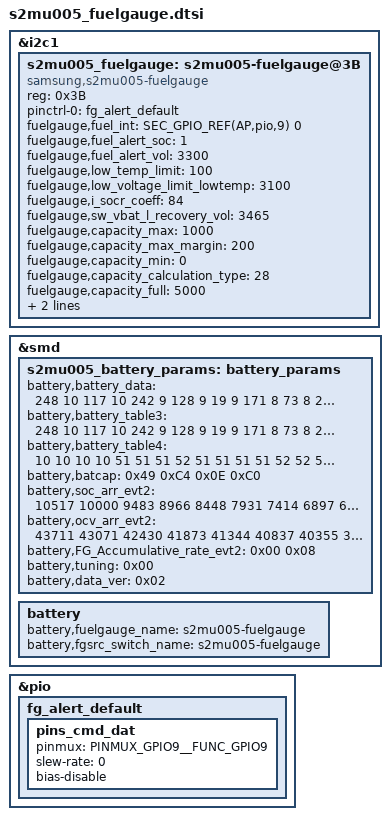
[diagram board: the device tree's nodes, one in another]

&i2c1 {
	status = "okay";

	s2mu005_fuelgauge: s2mu005-fuelgauge@3B {
		compatible = "samsung,s2mu005-fuelgauge";
		reg = <0x3B>;
		pinctrl-names = "default";
		pinctrl-0 = <&fg_alert_default>;
		fuelgauge,fuel_int = <SEC_GPIO_REF(AP,pio,9) 0>;
		fuelgauge,fuel_alert_soc = <1>;
		fuelgauge,fuel_alert_vol = <3300>;
		fuelgauge,low_temp_limit = <100>;
		fuelgauge,low_voltage_limit_lowtemp = <3100>;
		fuelgauge,i_socr_coeff = <84>;
		fuelgauge,sw_vbat_l_recovery_vol = <3465>;
		fuelgauge,capacity_max = <1000>;
		fuelgauge,capacity_max_margin = <200>;
		fuelgauge,capacity_min = <0>;
		fuelgauge,capacity_calculation_type = <28>;
		fuelgauge,capacity_full = <3000>;
		fuelgauge,type_str = "SDI";
		fuelgauge,fg_log_enable = <1>;
	};
};

&smd {
	s2mu005_battery_params: battery_params {
		battery,battery_data =
		<
			/***** battery data for 4.35 *****/
			/* battery,battery_table3 */
			6 11 132 10 1 10 138 9 23 9
			171 8 70 8 233 7 155 7 61 7
			223 6 169 6 128 6 96 6 70 6
			42 6 1 6 211 5 146 5 123 5
			223 3 7 2 107 8 0 8 149 7
			43 7 192 6 85 6 235 5 128 5
			21 5 171 4 64 4 213 3 107 3
			0 3 149 2 43 2 192 1 85 1
			235 0 128 0 21 0 241 15

			/* battery,battery_table4 */
			10 10 10 10 48 47 48 47 47 47
			47 48 49 50 51 54 57 64 77 106
			158 221

			/* battery,batcap */
			0x2B 0x14 0x8 0x13 /* [0x0F] [0x0E] [0x11] [0x10] */

			/* battery,accum */
			0x00 0x08 /* [0x44] [0x45] */

			/* battery,soc_arr_val */
			10521 10000 9479 8958 8438 7917 7396 6875 6354 5833
			5312 4791 4271 3750 3229 2708 2187 1667 1146 625
			104 (-75)

			/* battery,ocv_arr_val */
			43778 43142 42507 41922 41362 40834 40339 39890 39508 39047
			38588 38327 38126 37968 37843 37707 37507 37281 36962 36850
			34840 32536

			/* battery,tuning */
			0x00 /* [0x13] */

			/***** battery data for 4.33 *****/
			/* battery,battery_table3 */
			6 11 132 10 1 10 138 9 23 9
			171 8 70 8 233 7 155 7 61 7
			223 6 169 6 128 6 96 6 70 6
			42 6 1 6 211 5 146 5 123 5
			223 3 7 2 132 8 24 8 172 7
			65 7 213 6 105 6 253 5 145 5
			37 5 185 4 77 4 225 3 117 3
			9 3 157 2 49 2 197 1 89 1
			237 0 130 0 22 0 240 15

			/* battery,battery_table4 */
			10 10 10 10 48 47 48 47 47 47
			47 48 49 50 51 54 57 64 77 106
			158 221

			/* battery,batcap */
			0x2B 0x48 0x8 0x1D /* [0x0F] [0x0E] [0x11] [0x10] */

			/* battery,accum */
			0x00 0x8 /* [0x44] [0x45] */

			/* battery,soc_arr_val */
			10646 10119 9592 9065 8538 8011 7484 6957 6430 5903
			5376 4849 4321 3794 3267 2740 2213 1686 1159 632
			105 (-76)

			/* battery,ocv_arr_val */
			43778 43142 42507 41922 41362 40834 40339 39890 39508 39047
			38588 38327 38126 37968 37843 37707 37507 37281 36962 36850
			34840 32536

			/* battery,tuning */
			0x00 /* [0x13] */

			/***** battery data for 4.31 *****/
			/* battery,battery_table3 */
			6 11 132 10 1 10 138 9 23 9
			171 8 70 8 233 7 155 7 61 7
			223 6 169 6 128 6 96 6 70 6
			42 6 1 6 211 5 146 5 123 5
			223 3 7 2 203 8 92 8 236 7
			125 7 13 7 158 6 46 6 191 5
			79 5 224 4 113 4 1 4 146 3
			34 3 179 2 67 2 212 1 101 1
			245 0 134 0 22 0 240 15

			/* battery,battery_table4 */
			10 10 10 10 48 47 48 47 47 47
			47 48 49 50 51 54 57 64 77 106
			158 221

			/* battery,batcap */
			0x29 0xEC 0x7 0xDC /* [0x0F] [0x0E] [0x11] [0x10] */

			/* battery,accum */
			0x00 0x8 /* [0x44] [0x45] */

			/* battery,soc_arr_val */
			10992 10448 9903 9359 8815 8271 7727 7182 6638 6094
			5550 5006 4462 3918 3373 2829 2285 1741 1197 653
			109 (-79)

			/* battery,ocv_arr_val */
			43778 43142 42507 41922 41362 40834 40339 39890 39508 39047
			38588 38327 38126 37968 37843 37707 37507 37281 36962 36850
			34840 32536

			/* battery,tuning */
			0x00 /* [0x13] */

			/***** battery data for 4.29 *****/
			/* battery,battery_table3 */
			6 11 132 10 1 10 138 9 23 9
			171 8 70 8 233 7 155 7 61 7
			223 6 169 6 128 6 96 6 70 6
			42 6 1 6 211 5 146 5 123 5
			223 3 7 2 166 8 56 8 203 7
			93 7 240 6 130 6 20 6 167 5
			57 5 203 4 94 4 240 3 131 3
			21 3 167 2 58 2 204 1 95 1
			241 0 132 0 22 0 240 15

			/* battery,battery_table4 */
			10 10 10 10 48 47 48 47 47 47
			47 48 49 50 51 54 57 64 77 106
			158 221

			/* battery,batcap */
			0x2A 0xA0 0x7 0xFE /* [0x0F] [0x0E] [0x11] [0x10] */

			/* battery,accum */
			0x00 0x8 /* [0x44] [0x45] */

			/* battery,soc_arr_val */
			10810 10275 9740 9205 8670 8135 7599 7064 6529 5993
			5458 4923 4388 3853 3318 2783 2248 1712 1177 642
			107 (-77)

			/* battery,ocv_arr_val */
			43778 43142 42507 41922 41362 40834 40339 39890 39508 39047
			38588 38327 38126 37968 37843 37707 37507 37281 36962 36850
			34840 32536

			/* battery,tuning */
			0x00 /* [0x13] */

			/***** battery data for 4.24 *****/
			/* battery,battery_table3 */
			6 11 132 10 1 10 138 9 23 9
			171 8 70 8 233 7 155 7 61 7
			223 6 169 6 128 6 96 6 70 6
			42 6 1 6 211 5 146 5 123 5
			223 3 7 2 53 9 192 8 75 8
			215 7 98 7 237 6 121 6 4 6
			143 5 27 5 166 4 49 4 189 3
			72 3 211 2 95 2 234 1 117 1
			1 1 140 0 23 0 239 15

			/* battery,battery_table4 */
			10 10 10 10 48 47 48 47 47 47
			47 48 49 50 51 54 57 64 77 106
			158 221

			/* battery,batcap */
			0x28 0xC 0x7 0x82 /* [0x0F] [0x0E] [0x11] [0x10] */

			/* battery,accum */
			0x00 0x8 /* [0x44] [0x45] */

			/* battery,soc_arr_val */
			11507 10937 10367 9798 9228 8659 8089 7519 6949 6380
			5810 5240 4671 4101 3532 2962 2392 1823 1253 684
			114 (-82)

			/* battery,ocv_arr_val */
			43778 43142 42507 41922 41362 40834 40339 39890 39508 39047
			38588 38327 38126 37968 37843 37707 37507 37281 36962 36850
			34840 32536

			/* battery,tuning */
			0x00 /* [0x13] */
			>;

		battery,battery_table3 = <
			6 11 132 10 1 10 138 9 23 9
			171 8 70 8 233 7 155 7 61 7
			223 6 169 6 128 6 96 6 70 6
			42 6 1 6 211 5 146 5 123 5
			223 3 7 2 107 8 0 8 149 7
			43 7 192 6 85 6 235 5 128 5
			21 5 171 4 64 4 213 3 107 3
			0 3 149 2 43 2 192 1 85 1
			235 0 128 0 21 0 241 15
			>;

		battery,battery_table4 = <
			10 10 10 10 48 47 48 47 47 47
			47 48 49 50 51 54 57 64 77 106
			158 221
			>;

		battery,batcap = <0x2B 0x14 0x8 0x13>; /* [0x0F] [0x0E] [0x11] [0x10] */

		battery,soc_arr_evt2 = <
			10521 10000 9479 8958 8438 7917 7396 6875 6354 5833
			5312 4791 4271 3750 3229 2708 2187 1667 1146 625
			104 (-75)
			>;
		battery,ocv_arr_evt2 = <
			43778 43142 42507 41922 41362 40834 40339 39890 39508 39047
			38588 38327 38126 37968 37843 37707 37507 37281 36962 36850
			34840 32536
			>;
		battery,FG_Accumulative_rate_evt2 = <0x00 0x08>; /* 0x44 0x45 */
		battery,tuning = <0x00>; /* [0x13] */
		battery,data_ver = <0x04>;
	};
};

&smd {
	battery {
		battery,fuelgauge_name = "s2mu005-fuelgauge";
		battery,fgsrc_switch_name = "s2mu005-fuelgauge"; /* Fuelgauge voltage source */
	};
};

/* /home/dpi/qb5_8814/workspace/P4_1716/android/kernel/kmodule/battery/fuelgauge/s2mu005_fuelgauge/s2mu005_fuelgauge.a02.dtsi */

&pio {
	fg_alert_default: fg_alert_default {
		pins_cmd_dat {
			pinmux = <PINMUX_GPIO9__FUNC_GPIO9>;
			slew-rate = <0>;
			bias-disable;
		};
	};
};

&s2mu005_fuelgauge {
	fuelgauge,capacity_full = <5000>;
};

&s2mu005_battery_params {
	battery,battery_data =
	<
		/***** battery data for 4.35 *****/
		/* battery,battery_table3 */
		248 10 117 10 242 9 128 9 19 9
		171 8 73 8 208 7 156 7 70 7
		230 6 172 6 130 6 97 6 71 6
		45 6 7 6 223 5 155 5 130 5
		152 4 156 1 106 8 0 8 150 7
		44 7 194 6 88 6 238 5 132 5
		26 5 177 4 71 4 221 3 115 3
		9 3 159 2 53 2 203 1 97 1
		247 0 141 0 35 0 227 15

		/* battery,battery_table4 */
		10 10 10 10 51 51 51 52 51 51
		51 51 52 52 52 53 54 55 57 60
		65 154

		/* battery,batcap */
		0x49 0xC4 0x0E 0xC0 /* [0x0F] [0x0E] [0x11] [0x10] */

		/* battery,accum */
		0x00 0x08 /* [0x44] [0x45] */

		/* battery,soc_arr_val */
		10517 10000 9483 8966 8448 7931 7414 6897 6379 5862
		5345 4828 4310 3793 3276 2759 2241 1724 1207 690
		172 (-141)

		/* battery,ocv_arr_val */
		43711 43071 42430 41873 41344 40837 40355 39768 39513 39091
		38625 38338 38133 37972 37846 37721 37533 37336 37007 36884
		35744 32014

		/* battery,tuning */
		0x00 /* [0x13] */

		/***** battery data for 4.33 *****/
		/* battery,battery_table3 */
		233 10 108 10 239 9 123 9 11 9
		162 8 62 8 229 7 150 7 35 7
		216 6 166 6 126 6 94 6 68 6
		36 6 250 5 201 5 139 5 120 5
		98 3 90 1 118 8 11 8 159 7
		51 7 199 6 92 6 240 5 132 5
		24 5 173 4 65 4 213 3 105 3
		254 2 146 2 38 2 186 1 79 1
		227 0 119 0 11 0 136 15

		/* battery,battery_table4 */
		10 10 10 10 54 54 54 54 54 54
		54 54 55 55 56 56 56 57 59 63
		76 101

		/* battery,batcap */
		0x4B 0x5C 0x0F 0x12 /* [0x0F] [0x0E] [0x11] [0x10] */

		/* battery,accum */
		0x00 0x8 /* [0x44] [0x45] */

		/* battery,soc_arr_val */
		10578 10052 9525 8999 8473 7947 7421 6895 6369 5842
		5316 4790 4264 3738 3212 2686 2160 1633 1107 581
		55 (-584)

		/* battery,ocv_arr_val */
		43638 43028 42419 41849 41305 40789 40302 39869 39480 38923
		38557 38311 38115 37959 37830 37674 37472 37233 36929 36837
		34229 31691

		/* battery,tuning */
		0x00 /* [0x13] */

		/***** battery data for 4.31 *****/
		/* battery,battery_table3 */
		233 10 108 10 239 9 123 9 11 9
		162 8 62 8 229 7 150 7 35 7
		216 6 166 6 126 6 94 6 68 6
		36 6 250 5 201 5 139 5 120 5
		98 3 90 1 159 8 49 8 195 7
		85 7 232 6 122 6 12 6 158 5
		49 5 195 4 85 4 231 3 122 3
		12 3 158 2 48 2 195 1 85 1
		231 0 121 0 12 0 136 15

		/* battery,battery_table4 */
		10 10 10 10 54 54 54 54 54 54
		54 54 55 55 56 56 56 57 59 63
		76 101

		/* battery,batcap */
		0x49 0xF8 0x0E 0xCB /* [0x0F] [0x0E] [0x11] [0x10] */

		/* battery,accum */
		0x00 0x8 /* [0x44] [0x45] */

		/* battery,soc_arr_val */
		10774 10238 9702 9166 8630 8094 7559 7023 6487 5951
		5415 4879 4343 3807 3271 2736 2200 1664 1128 592
		56 (-586)

		/* battery,ocv_arr_val */
		43638 43028 42419 41849 41305 40789 40302 39869 39480 38923
		38557 38311 38115 37959 37830 37674 37472 37233 36929 36837
		34229 31691

		/* battery,tuning */
		0x00 /* [0x13] */

		/***** battery data for 4.29 *****/
		/* battery,battery_table3 */
		233 10 108 10 239 9 123 9 11 9
		162 8 62 8 229 7 150 7 35 7
		216 6 166 6 126 6 94 6 68 6
		36 6 250 5 201 5 139 5 120 5
		98 3 90 1 203 8 91 8 235 7
		123 7 11 7 155 6 43 6 187 5
		75 5 219 4 107 4 251 3 139 3
		27 3 171 2 60 2 204 1 92 1
		236 0 124 0 12 0 136 15

		/* battery,battery_table4 */
		10 10 10 10 54 54 54 54 54 54
		54 54 55 55 56 56 56 57 59 63
		76 101

		/* battery,batcap */
		0x48 0x84 0x0E 0x80 /* [0x0F] [0x0E] [0x11] [0x10] */

		/* battery,accum */
		0x00 0x8 /* [0x44] [0x45] */

		/* battery,soc_arr_val */
		10990 10443 9897 9350 8803 8257 7710 7163 6617 6070
		5524 4977 4430 3884 3337 2790 2244 1697 1150 604
		57 (-588)

		/* battery,ocv_arr_val */
		43638 43028 42419 41849 41305 40789 40302 39869 39480 38923
		38557 38311 38115 37959 37830 37674 37472 37233 36929 36837
		34229 31691

		/* battery,tuning */
		0x00 /* [0x13] */

		/***** battery data for 4.24 *****/
		/* battery,battery_table3 */
		233 10 108 10 239 9 123 9 11 9
		162 8 62 8 229 7 150 7 35 7
		216 6 166 6 126 6 94 6 68 6
		36 6 250 5 201 5 139 5 120 5
		98 3 90 1 54 9 192 8 75 8
		214 7 97 7 235 6 118 6 1 6
		139 5 22 5 161 4 44 4 182 3
		65 3 204 2 87 2 225 1 108 1
		247 0 130 0 12 0 136 15

		/* battery,battery_table4 */
		10 10 10 10 54 54 54 54 54 54
		54 54 55 55 56 56 56 57 59 63
		76 101

		/* battery,batcap */
		0x45 0x3C 0x0D 0xD8 /* [0x0F] [0x0E] [0x11] [0x10] */

		/* battery,accum */
		0x00 0x8 /* [0x44] [0x45] */

		/* battery,soc_arr_val */
		11511 10939 10366 9793 9221 8648 8076 7503 6931 6358
		5786 5213 4640 4068 3495 2923 2350 1778 1205 632
		60 (-592)

		/* battery,ocv_arr_val */
		43638 43028 42419 41849 41305 40789 40302 39869 39480 38923
		38557 38311 38115 37959 37830 37674 37472 37233 36929 36837
		34229 31691

		/* battery,tuning */
		0x00 /* [0x13] */
		>;

	battery,battery_table3 = <
		248 10 117 10 242 9 128 9 19 9
		171 8 73 8 208 7 156 7 70 7
		230 6 172 6 130 6 97 6 71 6
		45 6 7 6 223 5 155 5 130 5
		152 4 156 1 106 8 0 8 150 7
		44 7 194 6 88 6 238 5 132 5
		26 5 177 4 71 4 221 3 115 3
		9 3 159 2 53 2 203 1 97 1
		247 0 141 0 35 0 227 15
		>;

	battery,battery_table4 = <
		10 10 10 10 51 51 51 52 51 51
		51 51 52 52 52 53 54 55 57 60
		65 154
		>;

	battery,batcap = <0x49 0xC4 0x0E 0xC0>; /* [0x0F] [0x0E] [0x11] [0x10] */

	battery,soc_arr_evt2 = <
		10517 10000 9483 8966 8448 7931 7414 6897 6379 5862
		5345 4828 4310 3793 3276 2759 2241 1724 1207 690
		172 (-141)
		>;
	battery,ocv_arr_evt2 = <
		43711 43071 42430 41873 41344 40837 40355 39768 39513 39091
		38625 38338 38133 37972 37846 37721 37533 37336 37007 36884
		35744 32014
		>;
	battery,FG_Accumulative_rate_evt2 = <0x00 0x08>; /* 0x44 0x45 */
	battery,tuning = <0x00>; /* [0x13] */
	battery,data_ver = <0x02>;
};

